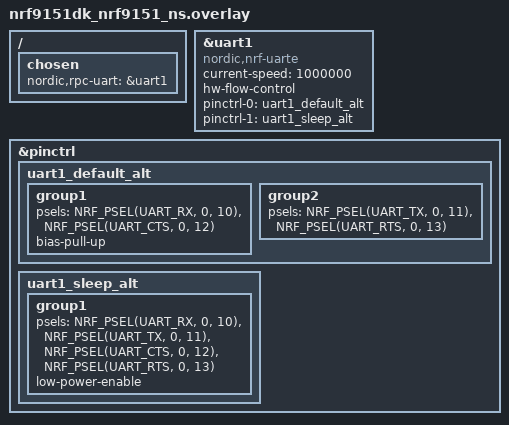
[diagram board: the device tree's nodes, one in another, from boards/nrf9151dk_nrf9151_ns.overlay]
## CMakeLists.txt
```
# Copyright (c) 2025 Nordic Semiconductor ASA
# SPDX-License-Identifier: LicenseRef-Nordic-5-Clause

cmake_minimum_required(VERSION 3.20.0)
find_package(Zephyr REQUIRED HINTS $ENV{ZEPHYR_BASE})
project(dect_rpc_client)

target_sources(app PRIVATE src/main.c)
target_sources_ifdef(CONFIG_SAMPLE_DECT_RPC_CLIENT_IPERF3 app PRIVATE src/iperf3_shell.c)
```

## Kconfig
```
#
# Copyright (c) 2026 Nordic Semiconductor ASA
#
# SPDX-License-Identifier: LicenseRef-Nordic-5-Clause
#

source "Kconfig.zephyr"

menu "DECT NR+ RPC client sample configuration"

config SAMPLE_DECT_RPC_CLIENT_IPERF3
	bool "iPerf3 (shell command)"
	select NRF_IPERF3
	help
	  Enable the ``iperf3`` shell command.

endmenu
```

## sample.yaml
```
# Copyright (c) 2026 Nordic Semiconductor ASA
# SPDX-License-Identifier: LicenseRef-Nordic-5-Clause

sample:
  name: DECT NR+ RPC client
common:
  tags:
    - ci_build
    - sysbuild
    - ci_samples_dect
  sysbuild: true
  build_only: true
  integration_platforms:
    - nrf9151dk/nrf9151/ns
  platform_allow:
    - nrf9151dk/nrf9151/ns

tests:
  sample.dect.dect_rpc_client: {}
  sample.dect.dect_rpc_client.rpc_uart_reliable:
    extra_args: EXTRA_CONF_FILE=rpc-uart-reliable.conf
  sample.dect.dect_rpc_client.iperf3_tx:
    extra_args: EXTRA_CONF_FILE="iperf3-common.conf;iperf3-tx.conf"
  sample.dect.dect_rpc_client.iperf3_rx:
    extra_args: EXTRA_CONF_FILE="iperf3-common.conf;iperf3-rx.conf"
```

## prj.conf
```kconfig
# DECT NR+ RPC client (no DECT modem on this device).

CONFIG_DECT_NR_RPC=y
CONFIG_DECT_NR_RPC_CLIENT=y
CONFIG_DECT_NR_RPC_NET_IF=y
CONFIG_NRF_RPC_UART_TRANSPORT=y
CONFIG_DECT_NR_RPC_UART_TRANSPORT=y

# Larger RX ring for non-reliable UART bursts (shell lines, IF_RECEIVE).
CONFIG_NRF_RPC_UART_RX_RINGBUF_SIZE=8192

CONFIG_NRF_RPC_CBOR=y
CONFIG_NRF_RPC_ZCBOR_BACKUPS=1
CONFIG_NRF_RPC_THREAD_STACK_SIZE=4096
CONFIG_NRF_RPC_THREAD_PRIORITY=0

# UART RPC: default is non-reliable (throughput). Use rpc-uart-reliable.conf on
# **both** client and server for per-frame ACK (noisy links).
CONFIG_NRF_RPC_UART_RELIABLE=n
CONFIG_NRF_RPC_RESPONSE_TIMEOUT=50

# Client is follower: do not send group init; wait for server to send it.
CONFIG_NRF_RPC_GROUP_DEFAULT_INITIATOR=n
CONFIG_NRF_RPC_GROUP_INIT_WAIT_TIME=-1

CONFIG_UART_LINE_CTRL=y
CONFIG_UART_INTERRUPT_DRIVEN=y

# Networking
CONFIG_NETWORKING=y
CONFIG_NET_NATIVE=y
CONFIG_NET_IPV6=y
CONFIG_NET_IPV4=n
CONFIG_NET_SOCKETS=y
CONFIG_NET_SOCKETS_OFFLOAD=n
CONFIG_NET_MAX_CONN=6
CONFIG_NET_STATISTICS=y

# ULA / DECT addressing; need room for e.g. link-local + ULA + global per iface.
CONFIG_NET_IF_UNICAST_IPV6_ADDR_COUNT=3

# Enough slots for addresses/prefixes synced from server
CONFIG_NET_IF_MAX_IPV6_COUNT=8
CONFIG_NET_INTERFACE_NAME=y

# Socket services
CONFIG_ZVFS_POLL_MAX=10

CONFIG_NET_BUF=y
CONFIG_NET_PKT_RX_COUNT=8
CONFIG_NET_BUF_RX_COUNT=16
CONFIG_NET_PKT_TX_COUNT=8
CONFIG_NET_BUF_TX_COUNT=16

# mDNS (responder + resolver + DNS-SD + hostname): use mdns.conf

# DNS resolver (unicast; use mdns.conf for *.local / mDNS advertise)
CONFIG_DNS_RESOLVER=y
CONFIG_DNS_RESOLVER_AUTO_INIT=y
CONFIG_DNS_SERVER_IP_ADDRESSES=y
CONFIG_DNS_SERVER1="2001:4860:4860::8888"
CONFIG_NET_SOCKETS_DNS_TIMEOUT=8000

CONFIG_NET_HOSTNAME="dect-rpc-client"

CONFIG_HEAP_MEM_POOL_SIZE=4096
CONFIG_MAIN_STACK_SIZE=2048
CONFIG_SYSTEM_WORKQUEUE_STACK_SIZE=2048

# Logging
CONFIG_LOG=y
CONFIG_NET_LOG=y
CONFIG_NRF_RPC_TR_LOG_LEVEL_INF=y
CONFIG_NRF_RPC_LOG_LEVEL_INF=y

# Shell and console: serial UART
CONFIG_SHELL=y
CONFIG_SHELL_PROMPT_UART="dect_rpc_client:~$ "
CONFIG_SHELL_BACKEND_SERIAL=y
CONFIG_NET_SHELL=y
CONFIG_DECT_NR_RPC_CLIENT_SHELL=y

# Ensure logs go to shell UART only (not a separate UART backend)
CONFIG_LOG_BACKEND_UART=n
# Keep printk() ordering consistent with logging (modem_shell / dect_shell).
CONFIG_LOG_PRINTK=n

# TF-M
CONFIG_TFM_PROFILE_TYPE_MINIMAL=y
CONFIG_TFM_SECURE_UART0=y
CONFIG_TFM_LOG_LEVEL_SILENCE=n
CONFIG_TFM_EXCEPTION_INFO_DUMP=y
CONFIG_TFM_SPM_LOG_LEVEL_DEBUG=y

# Debugging
CONFIG_ASSERT=y
CONFIG_ASSERT_VERBOSE=y
CONFIG_RESET_ON_FATAL_ERROR=n
CONFIG_EXTRA_EXCEPTION_INFO=y
CONFIG_SYS_HEAP_RUNTIME_STATS=y
CONFIG_NET_DECT_RPC_LOG_LEVEL_INF=y
```

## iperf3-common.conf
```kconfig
# iperf3 common configuration.
# Build from this directory, e.g.:
#   west build -p -b nrf9151dk/nrf9151/ns -- -DEXTRA_CONF_FILE="iperf3-common.conf;iperf3-tx.conf"
#
# Disables DNS/mDNS and other extras not needed for raw throughput tests.

CONFIG_SAMPLE_DECT_RPC_CLIENT_IPERF3=y

CONFIG_NRF_RPC_THREAD_POOL_SIZE=5
CONFIG_NRF_RPC_CMD_CTX_POOL_SIZE=12

CONFIG_DNS_RESOLVER=n
CONFIG_DNS_SD=n
CONFIG_DNS_RESOLVER_AUTO_INIT=n
CONFIG_DNS_RESOLVER_CACHE=n
CONFIG_DNS_SERVER_IP_ADDRESSES=n
CONFIG_MDNS_RESOLVER=n
CONFIG_MDNS_RESPONDER=n
CONFIG_MDNS_RESPONDER_DNS_SD=n
CONFIG_NET_SOCKETS_PACKET=n
CONFIG_NET_SOCKETS_PACKET_DGRAM=n
CONFIG_NET_SOCKETS_INET_RAW=n

CONFIG_NRF_IPERF3_HOST_NAME="nrf-dect-rpc-client-iperf3"
CONFIG_NRF_IPERF3_RESULTS_WAIT_TIME=180
CONFIG_NRF_IPERF3_NONBLOCKING_CLIENT_CHANGES=n

CONFIG_NET_IPV4=n
CONFIG_NET_IPV6=y
CONFIG_NET_IP_ADDR_CHECK=n
CONFIG_NET_IF_MAX_IPV6_COUNT=4

CONFIG_NET_TCP=y
CONFIG_NET_TCP_WORKQ_STACK_SIZE=2048
CONFIG_NET_TCP_INIT_RETRANSMISSION_TIMEOUT=6000
CONFIG_NET_TCP_RETRY_COUNT=6
CONFIG_NET_TCP_ISN_RFC6528=n

CONFIG_POSIX_API=y
CONFIG_GETOPT_LONG=y
CONFIG_CJSON_LIB=y
CONFIG_ZVFS_POLL_MAX=12
CONFIG_NET_MAX_CONTEXTS=10
CONFIG_NET_MAX_CONN=10

CONFIG_NET_CONTEXT_RCVTIMEO=y
CONFIG_NET_CONTEXT_SNDTIMEO=y

CONFIG_NET_BUF=y
CONFIG_NET_BUF_DATA_SIZE=128
CONFIG_NET_BUF_POOL_USAGE=y
CONFIG_NET_TC_RX_COUNT=0

# iperf3 uses libc malloc(); UART RPC TX uses k_malloc per frame (~header + CBOR + payload).
CONFIG_COMMON_LIBC_MALLOC_ARENA_SIZE=18432
CONFIG_HEAP_MEM_POOL_SIZE=24576
CONFIG_MAIN_STACK_SIZE=4096
CONFIG_SHELL_CMD_BUFF_SIZE=2048
# iperf_main() runs on the shell thread; default 2048 overflows (same as DeSh).
CONFIG_SHELL_STACK_SIZE=9216

CONFIG_SYS_HEAP_RUNTIME_STATS=y

CONFIG_NRF_RPC_TR_LOG_LEVEL_INF=y
```

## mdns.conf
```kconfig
# Extra mDNS configuration: full mDNS — responder (advertise *.local) + resolver (query *.local).
# Not in default prj.conf to keep the minimal RPC + IP image smaller.

# Responder: advertise peer name on the link
CONFIG_MDNS_RESPONDER=y
CONFIG_DNS_SD=y
CONFIG_MDNS_RESPONDER_DNS_SD=y
CONFIG_NET_HOSTNAME_ENABLE=y
CONFIG_NET_HOSTNAME="dect_rpc_client"
CONFIG_NET_HOSTNAME_DYNAMIC=y

# Resolver: *.local queries to mDNS multicast
CONFIG_MDNS_RESOLVER=y

CONFIG_DNS_RESOLVER_MAX_SERVERS=2
CONFIG_DNS_SERVER2="2001:4860:4860::8844"
CONFIG_DNS_RESOLVER_CACHE=y
CONFIG_NET_SOCKETS_DNS_BACKOFF_INTERVAL=4000

# DNS_DISPATCHER_MAX_POLL grows with MAX_SERVERS + mcast + MDNS_RESPONDER iface count.
CONFIG_ZVFS_POLL_MAX=12

CONFIG_SHELL_STACK_SIZE=4096
```

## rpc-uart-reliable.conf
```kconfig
# Extra Kconfig fragment: nRF RPC UART reliable mode (per-frame HDLC ACK + retries).
# Use on both client and server with the same fragment.
#
# Build from this sample directory (see README):
#   west build -p -b nrf9151dk/nrf9151/ns -- -DEXTRA_CONF_FILE=rpc-uart-reliable.conf
#
CONFIG_NRF_RPC_UART_RELIABLE=y
CONFIG_NRF_RPC_UART_ACK_WAITING_TIME=1000
CONFIG_NRF_RPC_UART_TX_ATTEMPTS=7
```

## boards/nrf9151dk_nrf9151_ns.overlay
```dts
/*
 * Copyright (c) 2026 Nordic Semiconductor ASA
 *
 * SPDX-License-Identifier: LicenseRef-Nordic-5-Clause
 *
 * RPC over UART1.
 *
 * Pins: RX P0.10, TX P0.11, CTS P0.12, RTS P0.13 (cross TX-RX and RTS-CTS to peer).
 */

/ {
	chosen {
		nordic,rpc-uart = &uart1;
	};
};

&uart1 {
	compatible = "nordic,nrf-uarte";
	status = "okay";
	current-speed = <1000000>;
	hw-flow-control;

	pinctrl-0 = <&uart1_default_alt>;
	pinctrl-1 = <&uart1_sleep_alt>;
	pinctrl-names = "default", "sleep";
};

&pinctrl {
	uart1_default_alt: uart1_default_alt {
		group1 {
			psels = <NRF_PSEL(UART_RX, 0, 10)>,
				<NRF_PSEL(UART_CTS, 0, 12)>;
			bias-pull-up;
		};

		group2 {
			psels = <NRF_PSEL(UART_TX, 0, 11)>,
				<NRF_PSEL(UART_RTS, 0, 13)>;
		};
	};

	uart1_sleep_alt: uart1_sleep_alt {
		group1 {
			psels = <NRF_PSEL(UART_RX, 0, 10)>,
				<NRF_PSEL(UART_TX, 0, 11)>,
				<NRF_PSEL(UART_CTS, 0, 12)>,
				<NRF_PSEL(UART_RTS, 0, 13)>;
			low-power-enable;
		};
	};
};
```

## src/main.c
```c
/*
 * Copyright (c) 2025 Nordic Semiconductor ASA
 *
 * SPDX-License-Identifier: LicenseRef-Nordic-5-Clause
 *
 * DECT NR+ RPC client: exposes a DECT net_if that forwards IPv6 over UART to the dect RPC server.
 * Optional mdns.conf advertises hostname via mDNS.
 *
 */

#include <zephyr/kernel.h>
#include <zephyr/net/net_if.h>

#include <zephyr/logging/log.h>
#include <nrf_rpc.h>

#if defined(CONFIG_DECT_NR_RPC_CLIENT)
#include "dect_rpc_client_net.h"
#endif

LOG_MODULE_REGISTER(main, LOG_LEVEL_INF);

#if defined(CONFIG_DECT_NR_RPC_CLIENT) && !defined(CONFIG_NRF_RPC_INIT)
static void rpc_err_handler(const struct nrf_rpc_err_report *report)
{
	LOG_ERR("RPC error: %d", report->code);
}

static K_SEM_DEFINE(rpc_bound_sem, 0, 1);

static void bound_handler(const struct nrf_rpc_group *group)
{
	if (group == dect_rpc_client_get_group()) {
		k_sem_give(&rpc_bound_sem);
	}
}
#endif

int main(void)
{
#if defined(CONFIG_DECT_NR_RPC_CLIENT) && !defined(CONFIG_NRF_RPC_INIT)
	nrf_rpc_set_bound_handler(bound_handler);
	LOG_INF("Initializing RPC...");
	int err;

	err = nrf_rpc_init(rpc_err_handler);
	if (err != 0) {
		LOG_ERR("nrf_rpc_init failed: %d", err);
		return err;
	}
	/* Wait until server sends group init (same idea as OpenThread: know when peer is ready). */
	LOG_INF("Waiting for server... (start server now)");
	if (k_sem_take(&rpc_bound_sem, K_MSEC(15000)) != 0) {
		LOG_ERR("Timeout waiting for RPC group (server not connected?)");
		return -ETIMEDOUT;
	}
	LOG_INF("RPC initialized (server ready)");
	dect_rpc_client_notify_rpc_init_done();
#endif

	if (net_if_get_by_name(CONFIG_DECT_NR_RPC_CLIENT_IFACE_NAME) < 0) {
		LOG_ERR("No DECT RPC interface named \"%s\" (CONFIG_NET_INTERFACE_NAME?)",
			CONFIG_DECT_NR_RPC_CLIENT_IFACE_NAME);
		return -ENOENT;
	}

	/* Do not call net_if_up() here as using DECT_RPC_L2 flag NET_IF_NO_AUTO_START */
	LOG_INF("DECT RPC client running. Interface is down; bring up with: net if up %s",
		CONFIG_DECT_NR_RPC_CLIENT_IFACE_NAME);
#if IS_ENABLED(CONFIG_NET_HOSTNAME_ENABLE)
	LOG_INF("mDNS name: %s.local (resolve from server or other hosts on link)",
		CONFIG_NET_HOSTNAME);
#endif

	return 0;
}
```

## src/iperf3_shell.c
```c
/*
 * Copyright (c) 2026 Nordic Semiconductor ASA
 *
 * SPDX-License-Identifier: LicenseRef-Nordic-5-Clause
 */

#include <zephyr/init.h>
#include <zephyr/kernel.h>
#include <zephyr/shell/shell.h>
#include <zephyr/posix/sys/select.h>
#include <iperf_api.h>

static int cmd_iperf3(const struct shell *shell, size_t argc, char **argv)
{
	ARG_UNUSED(shell);

	(void)iperf_main(argc, argv, NULL, 0, NULL);
	return 0;
}

SHELL_CMD_REGISTER(iperf3, NULL, "iPerf3 (try: iperf3 --manual)", cmd_iperf3);
```
